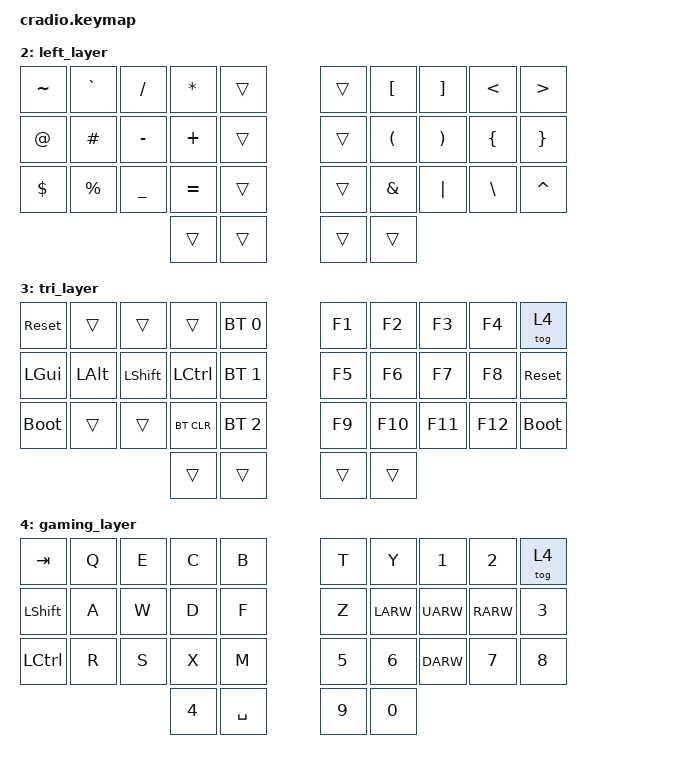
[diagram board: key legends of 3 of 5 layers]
// Copyright (c) 2022 The ZMK Contributors
// SPDX-License-Identifier: MIT

#include <behaviors.dtsi>
#include <dt-bindings/zmk/keys.h>
#include <dt-bindings/zmk/bt.h>

// Home row mods macro
#define HRML(k1,k2,k3,k4) &tap_mod LGUI k1  &tap_mod LALT k2  &tap_mod LSHFT k3  &tap_mod LCTRL k4
#define HRMR(k1,k2,k3,k4) &tap_mod RCTRL k1  &c_tap_mod RSHFT k2  &d_tap_mod RALT k3  &tap_mod RGUI k4

#define RIGHT_HAND_KEYS <5 6 7 8 9 15 16 17 18 19 25 26 27 28 29 32 33>
#define LEFT_HAND_KEYS <0 1 2 3 4 10 11 12 13 14 20 21 22 23 24 30 31>

/ {
    behaviors {
        tap_mod: regular_tap_mod {
            compatible = "zmk,behavior-hold-tap";
            #binding-cells = <2>;
            flavor = "tap-preferred";
            tapping-term-ms = <200>;
            quick-tap-ms = <0>;
            bindings = <&kp>, <&kp>;
            quick-tap-ms = <200>;
        };

        c_tap_mod: comma_tap_mod {
            compatible = "zmk,behavior-hold-tap";
            #binding-cells = <2>;
            flavor = "tap-preferred";
            tapping-term-ms = <200>;
            quick-tap-ms = <0>;
            bindings = <&kp>, <&sft_c>;
            quick-tap-ms = <200>;
        };

        d_tap_mod: dot_tap_mod {
            compatible = "zmk,behavior-hold-tap";
            #binding-cells = <2>;
            flavor = "tap-preferred";
            tapping-term-ms = <200>;
            quick-tap-ms = <0>;
            bindings = <&kp>, <&sft_d>;
            quick-tap-ms = <200>;
        };

        sft_c: shift_comma {
            compatible = "zmk,behavior-mod-morph";
            label = "SHIFT_COMMA";
            #binding-cells = <0>;
            bindings = <&kp COMMA>, <&kp FSLH>;
            mods = <(MOD_LSFT|MOD_RSFT)>;
            keep-mods = <(MOD_LSFT|MOD_RSFT)>;
        };        

        sft_d: shift_dot {
            compatible = "zmk,behavior-mod-morph";
            label = "SHIFT_DOT";
            #binding-cells = <0>;
            bindings = <&kp DOT>, <&kp N1>;
            mods = <(MOD_LSFT|MOD_RSFT)>;
            keep-mods = <(MOD_LSFT|MOD_RSFT)>;
        };
        
        bs_del: backspace_delete {
            compatible = "zmk,behavior-mod-morph";
            label = "BACKSPACE_DELETE";
            #binding-cells = <0>;
            bindings = <&kp BACKSPACE>, <&kp DELETE>;
            mods = <(MOD_LSFT|MOD_RSFT)>;
        };

        lt_bspc: layer_tap_bs_del {
            compatible = "zmk,behavior-hold-tap";
            label = "LAYER_TAP_BACKSPACE_DELETE";
            #binding-cells = <2>;
            bindings = <&mo>, <&bs_del>;
            tapping-term-ms = <300>;
            quick-tap-ms = <200>;
        };
    };

    conditional_layers {
        compatible = "zmk,conditional-layers";
        tri_layer {
            if-layers = <1 2>;
            then-layer = <3>;
        };
    };

    keymap {
        compatible = "zmk,keymap";
        default_layer {
            bindings = <
        //╭──────────┬──────────┬──────────┬──────────┬──────────╮   ╭──────────┬──────────┬──────────┬──────────┬──────────╮
        //│  Q       │  W       │  F       │  P       │  B       │   │  J       │  L       │  U       │  Y       │ ; :      │
            &kp Q      &kp W      &kp F      &kp P      &kp B          &kp J      &kp L      &kp U      &kp Y      &kp SEMI
        //├──────────┼──────────┼──────────┼──────────┼──────────┤   ├──────────┼──────────┼──────────┼──────────┼──────────┤
        //│  A       │  R       │  S       │  T       │  G       │   │  M       │  N       │  E       │  I       │ O        │
            &kp A      &kp R      &kp S      &kp T     &kp G          &kp M      &kp N      &kp E      &kp I      &kp O
        //├──────────┼──────────┼──────────┼──────────┼──────────┤   ├──────────┼──────────┼──────────┼──────────┼──────────┤
        //│  Z       │  X       │  C       │  D       │  V       │   │  K       │  H       │ , ?      │ . !      │ '' ""    │ 
             HRML(Z,        X,         C,         D)    &kp V          &kp K      HRMR(H,        0,         0,        QUOT) 
        //╰──────────┴──────────┴──────────┼──────────┼──────────┤   ├──────────┼──────────┼──────────┴──────────┴──────────╯
                                            &lt 2 TAB   &kp ENTER     &kp SPACE  &lt_bspc 1 0  // SFT + BSPC = DEL
        //                                 ╰──────────┴──────────╯   ╰──────────┴──────────╯
            >;
        };

        right_layer {
            bindings = <
        //╭──────────┬──────────┬──────────┬──────────┬──────────╮   ╭──────────┬──────────┬──────────┬──────────┬──────────╮
        //│ ESC      │  7       │  8       │  9       │          │   │ MUTE     │ VOL DN   │ VOL UP   │ BRT DN   │ BRT UP   │
            &kp ESC    &kp N7     &kp N8     &kp N9     &trans       &kp C_MUTE &kp C_VOL_DN &kp C_VOL_UP &kp C_BRI_DN &kp C_BRI_UP
        //├──────────┼──────────┼──────────┼──────────┼──────────┤   ├──────────┼──────────┼──────────┼──────────┼──────────┤
        //│ 0        │  4       │  5       │  6       │          │   │ PAGE UP  │ LEFT     │ DOWN     │ UP       │ RIGHT    │
            &kp N0     &kp N4      &kp N5    &kp N6     &trans         &kp PG_UP  &kp LARW   &kp DARW   &kp UARW   &kp RARW   
        //├──────────┼──────────┼──────────┼──────────┼──────────┤   ├──────────┼──────────┼──────────┼──────────┼──────────┤
        //│ CAPS LOCK│  1       │  2       │  3       │          │   │ PAGE DN  │PLAY PAUSE│ HOME     │ END      │ INSERT   │
            HRML(CAPS,      N1,        N2,       N3)    &trans         &kp PG_DN  &kp C_PP   &kp HOME   &kp END    &kp INS
        //╰──────────┴──────────┴──────────┼──────────┼──────────┤   ├──────────┼──────────┼──────────┴──────────┴──────────╯
                                             &trans     &trans         &trans     &trans
        //                                 ╰──────────┴──────────╯   ╰──────────┴──────────╯
            >;
        };

        left_layer {
            bindings = <
        //╭──────────┬──────────┬──────────┬──────────┬──────────╮   ╭──────────┬──────────┬──────────┬──────────┬──────────╮
        //│  ~       │  `       │  /       │  *       │          │   │          │  [       │  ]       │  <       │  >       │
            &kp TILDE  &kp GRAVE  &kp FSLH   &kp ASTRK  &trans         &trans     &kp LBKT   &kp RBKT   &kp LT     &kp GT 
        //├──────────┼──────────┼──────────┼──────────┼──────────┤   ├──────────┼──────────┼──────────┼──────────┼──────────┤
        //│  @       │  #       │  -       │  +       │          │   │          │  (       │  )       │  {       │  }       │
            &kp AT     &kp HASH   &kp MINUS  &kp PLUS   &trans         &trans     &kp LPAR   &kp RPAR   &kp LBRC   &kp RBRC
        //├──────────┼──────────┼──────────┼──────────┼──────────┤   ├──────────┼──────────┼──────────┼──────────┼──────────┤
        //│  $       │  %       │  _       │  =       │          │   │          │  &       │  |       │  \       │  ^       │
            &kp DLLR   &kp PRCNT  &kp UNDER  &kp EQUAL  &trans         &trans     &kp AMPS   &kp PIPE   &kp BSLH   &kp CARET
        //╰──────────┴──────────┴──────────┼──────────┼──────────┤   ├──────────┼──────────┼──────────┴──────────┴──────────╯
                                             &trans     &trans         &trans     &trans
        //                                 ╰──────────┴──────────╯   ╰──────────┴──────────╯
            >;
        };

        tri_layer {
            bindings = <
        //╭──────────┬──────────┬──────────┬──────────┬──────────╮   ╭──────────┬──────────┬──────────┬──────────┬──────────╮
        //│ RESET    │          │          │          │PROFILE 0 │   │          │          │          │          │          │
           &sys_reset  &trans     &trans     &trans    &bt BT_SEL 0    &kp F1     &kp F2     &kp F3     &kp F4     &tog 4
        //├──────────┼──────────┼──────────┼──────────┼──────────┤   ├──────────┼──────────┼──────────┼──────────┼──────────┤
        //│ GUI      │ ALT      │ SHIFT    │ CTRL     │PROFILE 1 │   │          │          │          │          │ RESET    │
           &kp LGUI   &kp LALT   &kp LSHFT  &kp LCTRL  &bt BT_SEL 1    &kp F5     &kp F6     &kp F7     &kp F8     &sys_reset
        //├──────────┼──────────┼──────────┼──────────┼──────────┤   ├──────────┼──────────┼──────────┼──────────┼──────────┤
        //│BOOTLOADER│          │          │ CLEAR BT │PROFILE 2 │   │          │          │          │          │BOOTLOADER│
          &bootloader  &trans     &trans    &bt BT_CLR &bt BT_SEL 2    &kp F9     &kp F10    &kp F11    &kp F12   &bootloader
        //╰──────────┴──────────┴──────────┼──────────┼──────────┤   ├──────────┼──────────┼──────────┴──────────┴──────────╯
                                             &trans     &trans         &trans     &trans
        //                                 ╰──────────┴──────────╯   ╰──────────┴──────────╯
            >;
        };

        gaming_layer {
            bindings = <
        //╭──────────┬──────────┬──────────┬──────────┬──────────╮   ╭──────────┬──────────┬──────────┬──────────┬──────────╮
        //│ TAB      │ Q        │ E        │ C        │ B        │   │          │          │          │          │          │
            &kp TAB    &kp Q      &kp E      &kp C      &kp B          &kp T      &kp Y      &kp N1     &kp N2     &tog 4
        //├──────────┼──────────┼──────────┼──────────┼──────────┤   ├──────────┼──────────┼──────────┼──────────┼──────────┤
        //│ SHIFT    │ A        │ W        │ D        │ F        │   │          │ LEFT     │ UP       │ RIGHT    │          │
            &kp LSHFT  &kp A      &kp W      &kp D      &kp F          &kp Z      &kp LARW   &kp UARW   &kp RARW   &kp N3
        //├──────────┼──────────┼──────────┼──────────┼──────────┤   ├──────────┼──────────┼──────────┼──────────┼──────────┤
        //│ CTRL     │ R        │ S        │ X        │ M        │   │          │          │ DOWN     │          │          │
            &kp LCTRL  &kp R      &kp S      &kp X      &kp M          &kp N5     &kp N6     &kp DARW   &kp N7     &kp N8
        //╰──────────┴──────────┴──────────┼──────────┼──────────┤   ├──────────┼──────────┼──────────┴──────────┴──────────╯
                                             &kp N4    &kp SPACE       &kp N9     &kp N0
        //                                 ╰──────────┴──────────╯   ╰──────────┴──────────╯
            >;
        };
    };
};
